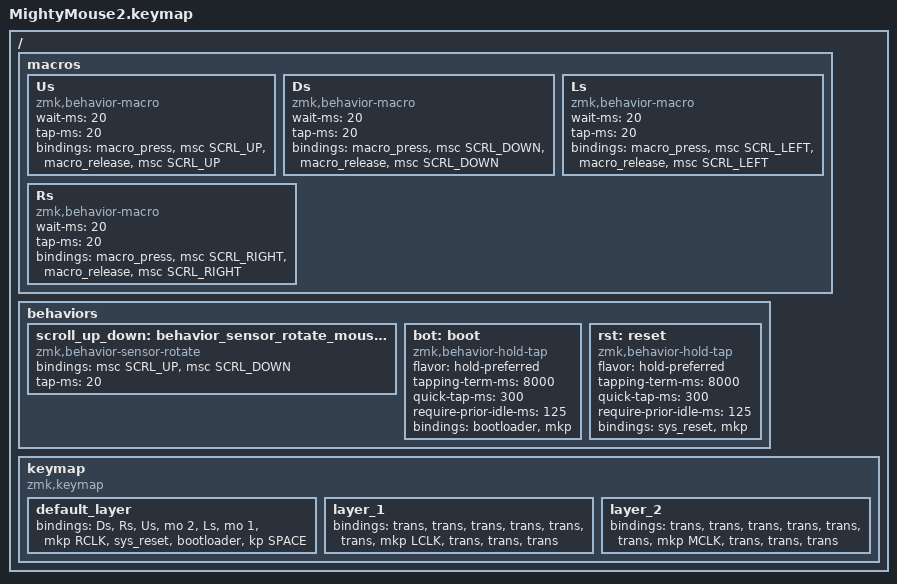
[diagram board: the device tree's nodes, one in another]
#include <behaviors.dtsi>
#include <dt-bindings/zmk/bt.h>
#include <dt-bindings/zmk/keys.h>
#include <dt-bindings/zmk/mouse.h>

#define ZMK_MOUSE_DEFAULT_SCRL_VAL 150   //スクロール量

/ {
    macros {
        Us: Us {
            compatible = "zmk,behavior-macro";
            #binding-cells = <0>;
            wait-ms = <20>;
            tap-ms = <20>;
            bindings = 
                <&macro_press &msc SCRL_UP>,
                <&macro_release &msc SCRL_UP>;
        };

        Ds: Ds {
            compatible = "zmk,behavior-macro";
            #binding-cells = <0>;
            wait-ms = <20>;
            tap-ms = <20>;
            bindings = 
                <&macro_press &msc SCRL_DOWN>,
                <&macro_release &msc SCRL_DOWN>;
        };

        Ls: Ls {
            compatible = "zmk,behavior-macro";
            #binding-cells = <0>;
            wait-ms = <20>;
            tap-ms = <20>;
            bindings = 
                <&macro_press &msc SCRL_LEFT>,
                <&macro_release &msc SCRL_LEFT>;
        };

        Rs: Rs {
            compatible = "zmk,behavior-macro";
            #binding-cells = <0>;
            wait-ms = <20>;
            tap-ms = <20>;
            bindings = 
                <&macro_press &msc SCRL_RIGHT>,
                <&macro_release &msc SCRL_RIGHT>;
        };
    };


    //新たな動作を定義する
    behaviors {
        scroll_up_down: behavior_sensor_rotate_mouse_wheel_up_down {
            compatible = "zmk,behavior-sensor-rotate";
            #sensor-binding-cells = <0>;
            bindings = <&msc SCRL_UP>, <&msc SCRL_DOWN>;
            // 追加: スクロールのタップ時間を設定 (20ms)
            tap-ms = <20>;
        };

            bot: boot {
            compatible = "zmk,behavior-hold-tap";
            #binding-cells = <2>;
            flavor = "hold-preferred";
            tapping-term-ms =<8000>;
            quick-tap-ms = <300>;
            require-prior-idle-ms = <125>;
            bindings = <&bootloader>, <&mkp>;
        };

            rst: reset {
            compatible = "zmk,behavior-hold-tap";
            #binding-cells = <2>;
            flavor = "hold-preferred";
            tapping-term-ms =<8000>;
            quick-tap-ms = <300>;
            require-prior-idle-ms = <125>;
            bindings = <&sys_reset>, <&mkp>;
        };

    };

    keymap {
        compatible = "zmk,keymap";

        default_layer {
            bindings = <
                //トラックボール
                &Ds
                &Rs
                &Us 
                &mo 2
                &Ls
                //クリックLR
                &mo 1
                &mkp RCLK
                //NFCfrontbottom
                    //&rst 0 MB5
                    //&bot 0 MB4
                    &sys_reset
                    &bootloader
                //add
                &kp SPACE
            >;

        };

        layer_1 {
            bindings = <
                //トラックボール
                &trans
                &trans
                &trans
                &trans
                &trans
                //クリック
                &trans
                &mkp LCLK
                //NFC
                &trans
                &trans
                &trans
            >;
        };

        layer_2 {
            bindings = <
                //トラックボール
                &trans
                &trans
                &trans
                &trans
                &trans
                //クリック
                &trans
                &mkp MCLK
                //NFC
                &trans
                &trans
                &trans
            >;
        };

    };
};
